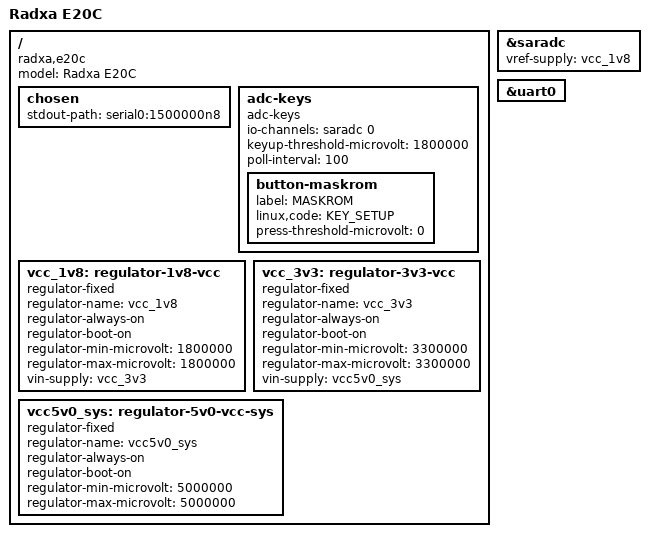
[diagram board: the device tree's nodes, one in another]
// SPDX-License-Identifier: GPL-2.0+
/*
 * Copyright (c) 2020 Rockchip Electronics Co., Ltd
 * Copyright (c) 2024 Radxa Limited
 * Copyright (c) 2024 Yao Zi <ziyao@disroot.org>
 */

/dts-v1/;

#include <dt-bindings/input/input.h>
#include "rk3528.dtsi"

/ {
	model = "Radxa E20C";
	compatible = "radxa,e20c", "rockchip,rk3528";

	chosen {
		stdout-path = "serial0:1500000n8";
	};

	adc-keys {
		compatible = "adc-keys";
		io-channels = <&saradc 0>;
		io-channel-names = "buttons";
		keyup-threshold-microvolt = <1800000>;
		poll-interval = <100>;

		button-maskrom {
			label = "MASKROM";
			linux,code = <KEY_SETUP>;
			press-threshold-microvolt = <0>;
		};
	};

	vcc_1v8: regulator-1v8-vcc {
		compatible = "regulator-fixed";
		regulator-name = "vcc_1v8";
		regulator-always-on;
		regulator-boot-on;
		regulator-min-microvolt = <1800000>;
		regulator-max-microvolt = <1800000>;
		vin-supply = <&vcc_3v3>;
	};

	vcc_3v3: regulator-3v3-vcc {
		compatible = "regulator-fixed";
		regulator-name = "vcc_3v3";
		regulator-always-on;
		regulator-boot-on;
		regulator-min-microvolt = <3300000>;
		regulator-max-microvolt = <3300000>;
		vin-supply = <&vcc5v0_sys>;
	};

	vcc5v0_sys: regulator-5v0-vcc-sys {
		compatible = "regulator-fixed";
		regulator-name = "vcc5v0_sys";
		regulator-always-on;
		regulator-boot-on;
		regulator-min-microvolt = <5000000>;
		regulator-max-microvolt = <5000000>;
	};
};

&saradc {
	vref-supply = <&vcc_1v8>;
	status = "okay";
};

&uart0 {
	status = "okay";
};
